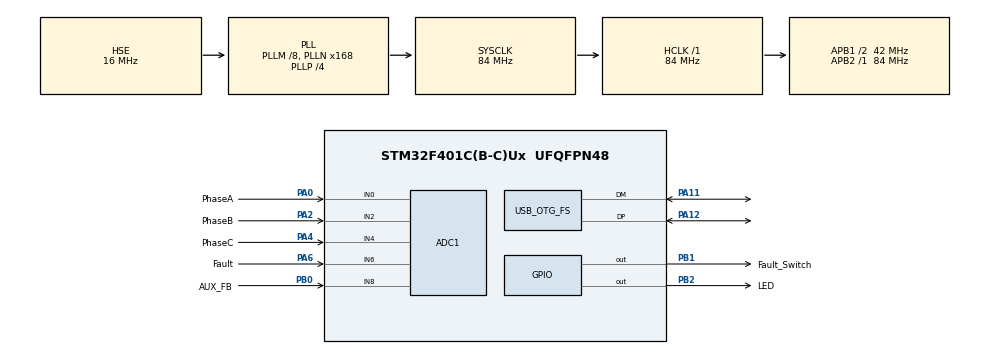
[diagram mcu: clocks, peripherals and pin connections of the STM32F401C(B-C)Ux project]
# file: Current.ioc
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ADC1.Channel-5\#ChannelRegularConversion=ADC_CHANNEL_0
ADC1.Channel-6\#ChannelRegularConversion=ADC_CHANNEL_2
ADC1.Channel-7\#ChannelRegularConversion=ADC_CHANNEL_4
ADC1.Channel-8\#ChannelRegularConversion=ADC_CHANNEL_6
ADC1.Channel-9\#ChannelRegularConversion=ADC_CHANNEL_8
ADC1.DMAContinuousRequests=ENABLE
ADC1.DiscontinuousConvMode=DISABLE
ADC1.EOCSelection=ADC_EOC_SEQ_CONV
ADC1.ExternalTrigConv=ADC_EXTERNALTRIGCONV_T2_TRGO
ADC1.ExternalTrigConvEdge=ADC_EXTERNALTRIGCONVEDGE_RISING
ADC1.NbrOfConversion=5
ADC1.NbrOfConversionFlag=1
ADC1.Rank-5\#ChannelRegularConversion=1
ADC1.Rank-6\#ChannelRegularConversion=2
ADC1.Rank-7\#ChannelRegularConversion=3
ADC1.Rank-8\#ChannelRegularConversion=4
ADC1.Rank-9\#ChannelRegularConversion=5
ADC1.SamplingTime-5\#ChannelRegularConversion=ADC_SAMPLETIME_480CYCLES
ADC1.SamplingTime-6\#ChannelRegularConversion=ADC_SAMPLETIME_480CYCLES
ADC1.SamplingTime-7\#ChannelRegularConversion=ADC_SAMPLETIME_480CYCLES
ADC1.SamplingTime-8\#ChannelRegularConversion=ADC_SAMPLETIME_480CYCLES
ADC1.SamplingTime-9\#ChannelRegularConversion=ADC_SAMPLETIME_480CYCLES
ADC1.master=1
Dma.ADC1.0.Direction=DMA_PERIPH_TO_MEMORY
Dma.ADC1.0.FIFOMode=DMA_FIFOMODE_DISABLE
Dma.ADC1.0.Instance=DMA2_Stream0
Dma.ADC1.0.MemDataAlignment=DMA_MDATAALIGN_HALFWORD
Dma.ADC1.0.MemInc=DMA_MINC_ENABLE
Dma.ADC1.0.Mode=DMA_CIRCULAR
Dma.ADC1.0.PeriphDataAlignment=DMA_PDATAALIGN_HALFWORD
Dma.ADC1.0.PeriphInc=DMA_PINC_DISABLE
Dma.ADC1.0.Priority=DMA_PRIORITY_LOW
Dma.Request0=ADC1
Mcu.Family=STM32F4
Mcu.Name=STM32F401C(B-C)Ux
Mcu.Package=UFQFPN48
NVIC.DMA2_Stream0_IRQn=true\:0\:0\:false\:false\:true\:false\:true\:true
NVIC.OTG_FS_IRQn=true\:0\:0\:false\:false\:true\:false\:true\:true
NVIC.PriorityGroup=NVIC_PRIORITYGROUP_4
PA0-WKUP.GPIO_Label=PhaseA
PA0-WKUP.Signal=ADCx_IN0
PA11.Mode=Device_Only
PA11.Signal=USB_OTG_FS_DM
PA12.Mode=Device_Only
PA12.Signal=USB_OTG_FS_DP
PA13.Mode=Trace_Asynchronous_SW
PA13.Signal=SYS_JTMS-SWDIO
PA14.Mode=Trace_Asynchronous_SW
PA14.Signal=SYS_JTCK-SWCLK
PA2.GPIO_Label=PhaseB
PA2.Signal=ADCx_IN2
PA4.GPIO_Label=PhaseC
PA4.Signal=ADCx_IN4
PA6.GPIO_Label=Fault
PA6.Signal=ADCx_IN6
PB0.GPIO_Label=AUX_FB
PB0.Signal=ADCx_IN8
PB1.GPIO_Label=Fault_Switch
PB1.Signal=GPIO_Output
PB2.GPIO_Label=LED
PB2.Signal=GPIO_Output
PB3.Mode=Trace_Asynchronous_SW
PB3.Signal=SYS_JTDO-SWO
PH0\ -\ OSC_IN.Mode=HSE-External-Oscillator
PH0\ -\ OSC_IN.Signal=RCC_OSC_IN
PH1\ -\ OSC_OUT.Mode=HSE-External-Oscillator
PH1\ -\ OSC_OUT.Signal=RCC_OSC_OUT
ProjectManager.HeapSize=0x200
ProjectManager.StackSize=0x400
ProjectManager.TargetToolchain=Makefile
RCC.48MHZClocksFreq_Value=48000000
RCC.AHBFreq_Value=84000000
RCC.APB1CLKDivider=RCC_HCLK_DIV2
RCC.APB1Freq_Value=42000000
RCC.APB1TimFreq_Value=84000000
RCC.APB2Freq_Value=84000000
RCC.APB2TimFreq_Value=84000000
RCC.CortexFreq_Value=84000000
RCC.HCLKFreq_Value=84000000
RCC.HSE_VALUE=16000000
RCC.HSI_VALUE=16000000
RCC.LSE_VALUE=32768
RCC.PLLM=8
RCC.PLLN=168
RCC.PLLP=RCC_PLLP_DIV4
RCC.PLLQ=7
RCC.SYSCLKFreq_VALUE=84000000
RCC.SYSCLKSource=RCC_SYSCLKSOURCE_PLLCLK
RCC.VCOOutputFreq_Value=336000000
SH.ADCx_IN0.0=ADC1_IN0,IN0
SH.ADCx_IN2.0=ADC1_IN2,IN2
SH.ADCx_IN4.0=ADC1_IN4,IN4
SH.ADCx_IN6.0=ADC1_IN6,IN6
SH.ADCx_IN8.0=ADC1_IN8,IN8
TIM2.AutoReloadPreload=TIM_AUTORELOAD_PRELOAD_ENABLE
TIM2.Period=21000-1
TIM2.Prescaler=1-1
TIM2.TIM_MasterOutputTrigger=TIM_TRGO_UPDATE
TIM2.TIM_MasterSlaveMode=TIM_MASTERSLAVEMODE_DISABLE
USB_DEVICE.CLASS_NAME_FS=CDC
USB_DEVICE.VirtualMode=Cdc
USB_DEVICE.VirtualModeFS=Cdc_FS
USB_OTG_FS.VirtualMode=Device_Only
VP_CRC_VS_CRC.Mode=CRC_Activate
VP_TIM2_VS_ClockSourceINT.Mode=Internal
VP_USB_DEVICE_VS_USB_DEVICE_CDC_FS.Mode=CDC_FS
VP_WWDG_VS_WWDG.Mode=WWDG_Activate
WWDG.Counter=127
WWDG.Prescaler=WWDG_PRESCALER_8
WWDG.Window=127
board=custom

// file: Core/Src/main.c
/* USER CODE BEGIN Header */
/**
  ******************************************************************************
  * @file           : main.c
  * @brief          : Main program body
  ******************************************************************************
  * @attention
  *
  * <h2><center>&copy; Copyright (c) 2021 STMicroelectronics.
  * All rights reserved.</center></h2>
  *
  * This software component is licensed by ST under BSD 3-Clause license,
  * the "License"; You may not use this file except in compliance with the
  * License. You may obtain a copy of the License at:
  *                        opensource.org/licenses/BSD-3-Clause
  *
  ******************************************************************************
  */
/* USER CODE END Header */
#include "main.h"
#include "usb_device.h"

/* USER CODE BEGIN Includes */
#include <CurrentApp.h>
#include "CAProtocolStm.h"
/* USER CODE END Includes */

ADC_HandleTypeDef hadc1;
DMA_HandleTypeDef hdma_adc1;

CRC_HandleTypeDef hcrc;

TIM_HandleTypeDef htim2;

WWDG_HandleTypeDef hwwdg;

void SystemClock_Config(void);
static void MX_GPIO_Init(void);
static void MX_DMA_Init(void);
static void MX_TIM2_Init(void);
static void MX_ADC1_Init(void);
static void MX_WWDG_Init(void);
static void MX_CRC_Init(void);

/* USER CODE BEGIN 0 */

// See calibration.m how value is calculated.

/* USER CODE END 0 */

int main(void)
{

  /* MCU Configuration--------------------------------------------------------*/

  /* Reset of all peripherals, Initializes the Flash interface and the Systick. */
  HAL_Init();

  /* Configure the system clock */
  SystemClock_Config();

  /* USER CODE BEGIN SysInit */
  const char* bootMsg = CAonBoot();
  /* USER CODE END SysInit */

  /* Initialize all configured peripherals */
  MX_GPIO_Init();
  MX_DMA_Init();
  MX_TIM2_Init();
  MX_ADC1_Init();
  MX_USB_DEVICE_Init();
  MX_WWDG_Init();
  MX_CRC_Init();
  /* USER CODE BEGIN 2 */
  currentAppInit(&hadc1, &htim2, &hcrc);
  HAL_GPIO_WritePin(GPIOB, Fault_Switch_Pin, GPIO_PIN_SET);
  /* USER CODE END 2 */

  /* Infinite loop */
  /* USER CODE BEGIN WHILE */
  while (1)
  {
      HAL_WWDG_Refresh(&hwwdg);
      currentAppLoop(bootMsg);
    /* USER CODE END WHILE */

  }
}

void SystemClock_Config(void)
{
  RCC_OscInitTypeDef RCC_OscInitStruct = {0};
  RCC_ClkInitTypeDef RCC_ClkInitStruct = {0};

  /** Configure the main internal regulator output voltage
  */
  __HAL_RCC_PWR_CLK_ENABLE();
  __HAL_PWR_VOLTAGESCALING_CONFIG(PWR_REGULATOR_VOLTAGE_SCALE2);

  /** Initializes the RCC Oscillators according to the specified parameters
  * in the RCC_OscInitTypeDef structure.
  */
  RCC_OscInitStruct.OscillatorType = RCC_OSCILLATORTYPE_HSE;
  RCC_OscInitStruct.HSEState = RCC_HSE_ON;
  RCC_OscInitStruct.PLL.PLLState = RCC_PLL_ON;
  RCC_OscInitStruct.PLL.PLLSource = RCC_PLLSOURCE_HSE;
  RCC_OscInitStruct.PLL.PLLM = 8;
  RCC_OscInitStruct.PLL.PLLN = 168;
  RCC_OscInitStruct.PLL.PLLP = RCC_PLLP_DIV4;
  RCC_OscInitStruct.PLL.PLLQ = 7;
  if (HAL_RCC_OscConfig(&RCC_OscInitStruct) != HAL_OK)
  {
    Error_Handler();
  }

  /** Initializes the CPU, AHB and APB buses clocks
  */
  RCC_ClkInitStruct.ClockType = RCC_CLOCKTYPE_HCLK|RCC_CLOCKTYPE_SYSCLK
                              |RCC_CLOCKTYPE_PCLK1|RCC_CLOCKTYPE_PCLK2;
  RCC_ClkInitStruct.SYSCLKSource = RCC_SYSCLKSOURCE_PLLCLK;
  RCC_ClkInitStruct.AHBCLKDivider = RCC_SYSCLK_DIV1;
  RCC_ClkInitStruct.APB1CLKDivider = RCC_HCLK_DIV2;
  RCC_ClkInitStruct.APB2CLKDivider = RCC_HCLK_DIV1;

  if (HAL_RCC_ClockConfig(&RCC_ClkInitStruct, FLASH_LATENCY_2) != HAL_OK)
  {
    Error_Handler();
  }
}

static void MX_ADC1_Init(void)
{

  ADC_ChannelConfTypeDef sConfig = {0};

  /** Configure the global features of the ADC (Clock, Resolution, Data Alignment and number of conversion)
  */
  hadc1.Instance = ADC1;
  hadc1.Init.ClockPrescaler = ADC_CLOCK_SYNC_PCLK_DIV4;
  hadc1.Init.Resolution = ADC_RESOLUTION_12B;
  hadc1.Init.ScanConvMode = ENABLE;
  hadc1.Init.ContinuousConvMode = DISABLE;
  hadc1.Init.DiscontinuousConvMode = DISABLE;
  hadc1.Init.ExternalTrigConvEdge = ADC_EXTERNALTRIGCONVEDGE_RISING;
  hadc1.Init.ExternalTrigConv = ADC_EXTERNALTRIGCONV_T2_TRGO;
  hadc1.Init.DataAlign = ADC_DATAALIGN_RIGHT;
  hadc1.Init.NbrOfConversion = 5;
  hadc1.Init.DMAContinuousRequests = ENABLE;
  hadc1.Init.EOCSelection = ADC_EOC_SEQ_CONV;
  if (HAL_ADC_Init(&hadc1) != HAL_OK)
  {
    Error_Handler();
  }

  /** Configure for the selected ADC regular channel its corresponding rank in the sequencer and its sample time.
  */
  sConfig.Channel = ADC_CHANNEL_0;
  sConfig.Rank = 1;
  sConfig.SamplingTime = ADC_SAMPLETIME_480CYCLES;
  if (HAL_ADC_ConfigChannel(&hadc1, &sConfig) != HAL_OK)
  {
    Error_Handler();
  }

  /** Configure for the selected ADC regular channel its corresponding rank in the sequencer and its sample time.
  */
  sConfig.Channel = ADC_CHANNEL_2;
  sConfig.Rank = 2;
  if (HAL_ADC_ConfigChannel(&hadc1, &sConfig) != HAL_OK)
  {
    Error_Handler();
  }

  /** Configure for the selected ADC regular channel its corresponding rank in the sequencer and its sample time.
  */
  sConfig.Channel = ADC_CHANNEL_4;
  sConfig.Rank = 3;
  if (HAL_ADC_ConfigChannel(&hadc1, &sConfig) != HAL_OK)
  {
    Error_Handler();
  }

  /** Configure for the selected ADC regular channel its corresponding rank in the sequencer and its sample time.
  */
  sConfig.Channel = ADC_CHANNEL_6;
  sConfig.Rank = 4;
  if (HAL_ADC_ConfigChannel(&hadc1, &sConfig) != HAL_OK)
  {
    Error_Handler();
  }

  /** Configure for the selected ADC regular channel its corresponding rank in the sequencer and its sample time.
  */
  sConfig.Channel = ADC_CHANNEL_8;
  sConfig.Rank = 5;
  if (HAL_ADC_ConfigChannel(&hadc1, &sConfig) != HAL_OK)
  {
    Error_Handler();
  }

}

static void MX_CRC_Init(void)
{

  hcrc.Instance = CRC;
  if (HAL_CRC_Init(&hcrc) != HAL_OK)
  {
    Error_Handler();
  }

}

static void MX_TIM2_Init(void)
{

  TIM_ClockConfigTypeDef sClockSourceConfig = {0};
  TIM_MasterConfigTypeDef sMasterConfig = {0};

  htim2.Instance = TIM2;
  htim2.Init.Prescaler = 1-1;
  htim2.Init.CounterMode = TIM_COUNTERMODE_UP;
  htim2.Init.Period = 21000-1;
  htim2.Init.ClockDivision = TIM_CLOCKDIVISION_DIV1;
  htim2.Init.AutoReloadPreload = TIM_AUTORELOAD_PRELOAD_ENABLE;
  if (HAL_TIM_Base_Init(&htim2) != HAL_OK)
  {
    Error_Handler();
  }
  sClockSourceConfig.ClockSource = TIM_CLOCKSOURCE_INTERNAL;
  if (HAL_TIM_ConfigClockSource(&htim2, &sClockSourceConfig) != HAL_OK)
  {
    Error_Handler();
  }
  sMasterConfig.MasterOutputTrigger = TIM_TRGO_UPDATE;
  sMasterConfig.MasterSlaveMode = TIM_MASTERSLAVEMODE_DISABLE;
  if (HAL_TIMEx_MasterConfigSynchronization(&htim2, &sMasterConfig) != HAL_OK)
  {
    Error_Handler();
  }

}

static void MX_WWDG_Init(void)
{

  hwwdg.Instance = WWDG;
  hwwdg.Init.Prescaler = WWDG_PRESCALER_8;
  hwwdg.Init.Window = 127;
  hwwdg.Init.Counter = 127;
  hwwdg.Init.EWIMode = WWDG_EWI_DISABLE;
  if (HAL_WWDG_Init(&hwwdg) != HAL_OK)
  {
    Error_Handler();
  }

}

static void MX_DMA_Init(void)
{

  /* DMA controller clock enable */
  __HAL_RCC_DMA2_CLK_ENABLE();

  /* DMA interrupt init */
  /* DMA2_Stream0_IRQn interrupt configuration */
  HAL_NVIC_SetPriority(DMA2_Stream0_IRQn, 0, 0);
  HAL_NVIC_EnableIRQ(DMA2_Stream0_IRQn);

}

static void MX_GPIO_Init(void)
{
  GPIO_InitTypeDef GPIO_InitStruct = {0};

  /* GPIO Ports Clock Enable */
  __HAL_RCC_GPIOH_CLK_ENABLE();
  __HAL_RCC_GPIOA_CLK_ENABLE();
  __HAL_RCC_GPIOB_CLK_ENABLE();

  /*Configure GPIO pin Output Level */
  HAL_GPIO_WritePin(GPIOB, Fault_Switch_Pin|LED_Pin, GPIO_PIN_RESET);

  /*Configure GPIO pins : Fault_Switch_Pin LED_Pin */
  GPIO_InitStruct.Pin = Fault_Switch_Pin|LED_Pin;
  GPIO_InitStruct.Mode = GPIO_MODE_OUTPUT_PP;
  GPIO_InitStruct.Pull = GPIO_NOPULL;
  GPIO_InitStruct.Speed = GPIO_SPEED_FREQ_LOW;
  HAL_GPIO_Init(GPIOB, &GPIO_InitStruct);

}

void Error_Handler(void)
{
  __disable_irq();
  while (1)
  {
  }
}
